AUTOSAR XML (schema 00048)
package /MICROSAR/ComM_swc
  mode declaration group ComMMode: initial-mode=COMM_NO_COMMUNICATION
    mode COMM_NO_COMMUNICATION
    mode COMM_SILENT_COMMUNICATION
    mode COMM_FULL_COMMUNICATION
  data type mapping set ComMMode_DataTypeMappingSet: mode-request-type-map{implementation-data-type=ComM_ModeType, mode-group=ComMMode}  # Data Mapping for the Mode Declaration Group ComMMode.
package /MICROSAR/ComM_swc/DataTypes
  4 x impl type, all with category=TYPE_REFERENCE:
    ComM_ModeType: compu {0=COMM_NO_COMMUNICATION, 1=COMM_SILENT_COMMUNICATION, 2=COMM_FULL_COMMUNICATION}, range raw 0..3, implementation-data-type=uint8
    ComM_InhibitionStatusType: range raw 0..255, implementation-data-type=uint8
    ComM_UserHandleType: range raw 0..65535, implementation-data-type=uint16
    NetworkHandleType: range raw 0..255, implementation-data-type=uint8, type-emitter=ComM
package /MICROSAR/ComM_swc/Interfaces
  4 x client server interface, all with is-service=true, service-kind=COM-MANAGER:
    ComM_UserRequest
      5 x operation:
        RequestComMode: possible-error=[ComM_UserRequest/E_NOT_OK, E_MODE_LIMITATION]
          arg ComMode: type=ComM_ModeType, direction=IN
        GetCurrentComMode: possible-error=ComM_UserRequest/E_NOT_OK
          arg ComMode: type=ComM_ModeType, direction=OUT
        GetMaxComMode: possible-error=ComM_UserRequest/E_NOT_OK
          arg ComMode: type=ComM_ModeType, direction=OUT
        GetRequestedComMode: possible-error=ComM_UserRequest/E_NOT_OK
          arg ComMode: type=ComM_ModeType, direction=OUT
        GetCurrentPNCComMode: possible-error=[ComM_UserRequest/E_NOT_OK, E_MULTIPLE_PNC_ASSIGNED, COMM_E_NO_PNC_ASSIGNED]
          arg ComMode: type=ComM_ModeType, direction=OUT
      4 x error:
        E_NOT_OK: error-code=1
        E_MODE_LIMITATION: error-code=2
        E_MULTIPLE_PNC_ASSIGNED: error-code=4
        COMM_E_NO_PNC_ASSIGNED: error-code=5
    ComM_ECUModeLimitation
      4 x operation, all with possible-error=ComM_ECUModeLimitation/E_NOT_OK:
        LimitECUToNoComMode
          arg Status: type=boolean, direction=IN
        ReadInhibitCounter
          arg CounterValue: type=uint16, direction=OUT
        ResetInhibitCounter
        SetECUGroupClassification
          arg Status: type=ComM_InhibitionStatusType, direction=IN
      error E_NOT_OK: error-code=1
    ComM_ChannelWakeUp
      operation PreventWakeUp: possible-error=ComM_ChannelWakeUp/E_NOT_OK
        arg Status: type=boolean, direction=IN
      operation GetInhibitionStatus: possible-error=ComM_ChannelWakeUp/E_NOT_OK
        arg Status: type=ComM_InhibitionStatusType, direction=OUT
      error E_NOT_OK: error-code=1
    ComM_ChannelLimitation
      operation LimitChannelToNoComMode: possible-error=ComM_ChannelLimitation/E_NOT_OK
        arg Status: type=boolean, direction=IN
      operation GetInhibitionStatus: possible-error=ComM_ChannelLimitation/E_NOT_OK
        arg Status: type=ComM_InhibitionStatusType, direction=OUT
      error E_NOT_OK: error-code=1
  mode switch interface ComM_CurrentMode: is-service=true, service-kind=COM-MANAGER
    mode group currentMode: type=ComMMode
package /MICROSAR/ComM_swc/ComponentTypes
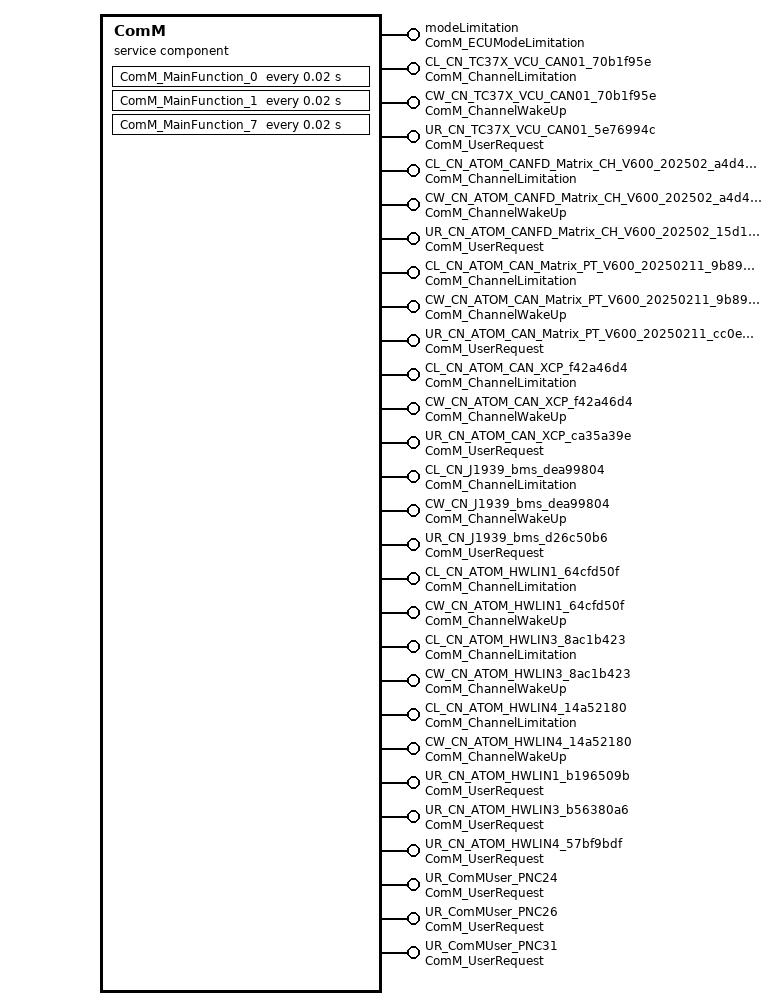
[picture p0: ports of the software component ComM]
  service sw component type ComM: category=SERVICE_COMPONENT
    28 x provide port:
      modeLimitation: provided-interface=ComM_ECUModeLimitation
      CL_CN_TC37X_VCU_CAN01_70b1f95e: provided-interface=ComM_ChannelLimitation
      CW_CN_TC37X_VCU_CAN01_70b1f95e: provided-interface=ComM_ChannelWakeUp
      UR_CN_TC37X_VCU_CAN01_5e76994c: provided-interface=ComM_UserRequest
      CL_CN_ATOM_CANFD_Matrix_CH_V600_202502_a4d436ac: provided-interface=ComM_ChannelLimitation
      CW_CN_ATOM_CANFD_Matrix_CH_V600_202502_a4d436ac: provided-interface=ComM_ChannelWakeUp
      UR_CN_ATOM_CANFD_Matrix_CH_V600_202502_15d11ab0: provided-interface=ComM_UserRequest
      CL_CN_ATOM_CAN_Matrix_PT_V600_20250211_9b894f3d: provided-interface=ComM_ChannelLimitation
      CW_CN_ATOM_CAN_Matrix_PT_V600_20250211_9b894f3d: provided-interface=ComM_ChannelWakeUp
      UR_CN_ATOM_CAN_Matrix_PT_V600_20250211_cc0efb79: provided-interface=ComM_UserRequest
      CL_CN_ATOM_CAN_XCP_f42a46d4: provided-interface=ComM_ChannelLimitation
      CW_CN_ATOM_CAN_XCP_f42a46d4: provided-interface=ComM_ChannelWakeUp
      UR_CN_ATOM_CAN_XCP_ca35a39e: provided-interface=ComM_UserRequest
      CL_CN_J1939_bms_dea99804: provided-interface=ComM_ChannelLimitation
      CW_CN_J1939_bms_dea99804: provided-interface=ComM_ChannelWakeUp
      UR_CN_J1939_bms_d26c50b6: provided-interface=ComM_UserRequest
      CL_CN_ATOM_HWLIN1_64cfd50f: provided-interface=ComM_ChannelLimitation
      CW_CN_ATOM_HWLIN1_64cfd50f: provided-interface=ComM_ChannelWakeUp
      CL_CN_ATOM_HWLIN3_8ac1b423: provided-interface=ComM_ChannelLimitation
      CW_CN_ATOM_HWLIN3_8ac1b423: provided-interface=ComM_ChannelWakeUp
      CL_CN_ATOM_HWLIN4_14a52180: provided-interface=ComM_ChannelLimitation
      CW_CN_ATOM_HWLIN4_14a52180: provided-interface=ComM_ChannelWakeUp
      UR_CN_ATOM_HWLIN1_b196509b: provided-interface=ComM_UserRequest
      UR_CN_ATOM_HWLIN3_b56380a6: provided-interface=ComM_UserRequest
      UR_CN_ATOM_HWLIN4_57bf9bdf: provided-interface=ComM_UserRequest
      UR_ComMUser_PNC24: provided-interface=ComM_UserRequest
      UR_ComMUser_PNC26: provided-interface=ComM_UserRequest
      UR_ComMUser_PNC31: provided-interface=ComM_UserRequest
    behavior ComMInternalBehavior: data-type-mapping=ComMMode_DataTypeMappingSet, handle-termination-and-restart=NO-SUPPORT, included-data-type-set=data-type=[ComM_ModeType, ComM_InhibitionStatusType, ComM_UserHandleType, NetworkHandleType]
      timing event Timer_ComM_MainFunction_0: start-on-event=ComM_MainFunction_0, period=0.02
      4 x operation invoked event:
        OpEventLimitECUToNoComMode_LimitECUToNoComMode_modeLimitation: start-on-event=LimitECUToNoComMode, operation=modeLimitation.LimitECUToNoComMode
        OpEventReadInhibitCounter_ReadInhibitCounter_modeLimitation: start-on-event=ReadInhibitCounter, operation=modeLimitation.ReadInhibitCounter
        OpEventResetInhibitCounter_ResetInhibitCounter_modeLimitation: start-on-event=ResetInhibitCounter, operation=modeLimitation.ResetInhibitCounter
        OpEventSetECUGroupClassification_SetECUGroupClassification_modeLimitation: start-on-event=SetECUGroupClassification, operation=modeLimitation.SetECUGroupClassification
      timing event Timer_ComM_MainFunction_1: start-on-event=ComM_MainFunction_1, period=0.02
      8 x operation invoked event:
        OpEventGetInhibitionStatus_GetInhibitionStatus_CL_CN_TC37X_VCU_CAN01_70b1f95e: start-on-event=GetInhibitionStatus, operation=CL_CN_TC37X_VCU_CAN01_70b1f95e.GetInhibitionStatus
        OpEventGetInhibitionStatus_GetInhibitionStatus_CW_CN_TC37X_VCU_CAN01_70b1f95e: start-on-event=GetInhibitionStatus, operation=CW_CN_TC37X_VCU_CAN01_70b1f95e.GetInhibitionStatus
        OpEventLimitChannelToNoComMode_LimitChannelToNoComMode_CL_CN_TC37X_VCU_CAN01_70b1f95e: start-on-event=LimitChannelToNoComMode, operation=CL_CN_TC37X_VCU_CAN01_70b1f95e.LimitChannelToNoComMode
        OpEventPreventWakeUp_PreventWakeUp_CW_CN_TC37X_VCU_CAN01_70b1f95e: start-on-event=PreventWakeUp, operation=CW_CN_TC37X_VCU_CAN01_70b1f95e.PreventWakeUp
        OpEventRequestComMode_RequestComMode_UR_CN_TC37X_VCU_CAN01_5e76994c: start-on-event=RequestComMode, operation=UR_CN_TC37X_VCU_CAN01_5e76994c.RequestComMode
        OpEventGetCurrentComMode_GetCurrentComMode_UR_CN_TC37X_VCU_CAN01_5e76994c: start-on-event=GetCurrentComMode, operation=UR_CN_TC37X_VCU_CAN01_5e76994c.GetCurrentComMode
        OpEventGetMaxComMode_GetMaxComMode_UR_CN_TC37X_VCU_CAN01_5e76994c: start-on-event=GetMaxComMode, operation=UR_CN_TC37X_VCU_CAN01_5e76994c.GetMaxComMode
        OpEventGetRequestedComMode_GetRequestedComMode_UR_CN_TC37X_VCU_CAN01_5e76994c: start-on-event=GetRequestedComMode, operation=UR_CN_TC37X_VCU_CAN01_5e76994c.GetRequestedComMode
      5 x timing event, all with period=0.02:
        Timer_ComM_MainFunction_{2..6}: start-on-event=ComM_MainFunction_{2..6}
      8 x operation invoked event:
        OpEventGetInhibitionStatus_GetInhibitionStatus_CL_CN_ATOM_CANFD_Matrix_CH_V600_202502_a4d436ac: start-on-event=GetInhibitionStatus, operation=CL_CN_ATOM_CANFD_Matrix_CH_V600_202502_a4d436ac.GetInhibitionStatus
        OpEventGetInhibitionStatus_GetInhibitionStatus_CW_CN_ATOM_CANFD_Matrix_CH_V600_202502_a4d436ac: start-on-event=GetInhibitionStatus, operation=CW_CN_ATOM_CANFD_Matrix_CH_V600_202502_a4d436ac.GetInhibitionStatus
        OpEventLimitChannelToNoComMode_LimitChannelToNoComMode_CL_CN_ATOM_CANFD_Matrix_CH_V600_202502_a4d436ac: start-on-event=LimitChannelToNoComMode, operation=CL_CN_ATOM_CANFD_Matrix_CH_V600_202502_a4d436ac.LimitChannelToNoComMode
        OpEventPreventWakeUp_PreventWakeUp_CW_CN_ATOM_CANFD_Matrix_CH_V600_202502_a4d436ac: start-on-event=PreventWakeUp, operation=CW_CN_ATOM_CANFD_Matrix_CH_V600_202502_a4d436ac.PreventWakeUp
        OpEventRequestComMode_RequestComMode_UR_CN_ATOM_CANFD_Matrix_CH_V600_202502_15d11ab0: start-on-event=RequestComMode, operation=UR_CN_ATOM_CANFD_Matrix_CH_V600_202502_15d11ab0.RequestComMode
        OpEventGetCurrentComMode_GetCurrentComMode_UR_CN_ATOM_CANFD_Matrix_CH_V600_202502_15d11ab0: start-on-event=GetCurrentComMode, operation=UR_CN_ATOM_CANFD_Matrix_CH_V600_202502_15d11ab0.GetCurrentComMode
        OpEventGetMaxComMode_GetMaxComMode_UR_CN_ATOM_CANFD_Matrix_CH_V600_202502_15d11ab0: start-on-event=GetMaxComMode, operation=UR_CN_ATOM_CANFD_Matrix_CH_V600_202502_15d11ab0.GetMaxComMode
        OpEventGetRequestedComMode_GetRequestedComMode_UR_CN_ATOM_CANFD_Matrix_CH_V600_202502_15d11ab0: start-on-event=GetRequestedComMode, operation=UR_CN_ATOM_CANFD_Matrix_CH_V600_202502_15d11ab0.GetRequestedComMode
      timing event Timer_ComM_MainFunction_7: start-on-event=ComM_MainFunction_7, period=0.02
      71 x operation invoked event:
        OpEventGetInhibitionStatus_GetInhibitionStatus_CL_CN_ATOM_CAN_Matrix_PT_V600_20250211_9b894f3d: start-on-event=GetInhibitionStatus, operation=CL_CN_ATOM_CAN_Matrix_PT_V600_20250211_9b894f3d.GetInhibitionStatus
        OpEventGetInhibitionStatus_GetInhibitionStatus_CW_CN_ATOM_CAN_Matrix_PT_V600_20250211_9b894f3d: start-on-event=GetInhibitionStatus, operation=CW_CN_ATOM_CAN_Matrix_PT_V600_20250211_9b894f3d.GetInhibitionStatus
        OpEventLimitChannelToNoComMode_LimitChannelToNoComMode_CL_CN_ATOM_CAN_Matrix_PT_V600_20250211_9b894f3d: start-on-event=LimitChannelToNoComMode, operation=CL_CN_ATOM_CAN_Matrix_PT_V600_20250211_9b894f3d.LimitChannelToNoComMode
        OpEventPreventWakeUp_PreventWakeUp_CW_CN_ATOM_CAN_Matrix_PT_V600_20250211_9b894f3d: start-on-event=PreventWakeUp, operation=CW_CN_ATOM_CAN_Matrix_PT_V600_20250211_9b894f3d.PreventWakeUp
        OpEventRequestComMode_RequestComMode_UR_CN_ATOM_CAN_Matrix_PT_V600_20250211_cc0efb79: start-on-event=RequestComMode, operation=UR_CN_ATOM_CAN_Matrix_PT_V600_20250211_cc0efb79.RequestComMode
        OpEventGetCurrentComMode_GetCurrentComMode_UR_CN_ATOM_CAN_Matrix_PT_V600_20250211_cc0efb79: start-on-event=GetCurrentComMode, operation=UR_CN_ATOM_CAN_Matrix_PT_V600_20250211_cc0efb79.GetCurrentComMode
        OpEventGetMaxComMode_GetMaxComMode_UR_CN_ATOM_CAN_Matrix_PT_V600_20250211_cc0efb79: start-on-event=GetMaxComMode, operation=UR_CN_ATOM_CAN_Matrix_PT_V600_20250211_cc0efb79.GetMaxComMode
        OpEventGetRequestedComMode_GetRequestedComMode_UR_CN_ATOM_CAN_Matrix_PT_V600_20250211_cc0efb79: start-on-event=GetRequestedComMode, operation=UR_CN_ATOM_CAN_Matrix_PT_V600_20250211_cc0efb79.GetRequestedComMode
        OpEventGetInhibitionStatus_GetInhibitionStatus_CL_CN_ATOM_CAN_XCP_f42a46d4: start-on-event=GetInhibitionStatus, operation=CL_CN_ATOM_CAN_XCP_f42a46d4.GetInhibitionStatus
        OpEventGetInhibitionStatus_GetInhibitionStatus_CW_CN_ATOM_CAN_XCP_f42a46d4: start-on-event=GetInhibitionStatus, operation=CW_CN_ATOM_CAN_XCP_f42a46d4.GetInhibitionStatus
        OpEventLimitChannelToNoComMode_LimitChannelToNoComMode_CL_CN_ATOM_CAN_XCP_f42a46d4: start-on-event=LimitChannelToNoComMode, operation=CL_CN_ATOM_CAN_XCP_f42a46d4.LimitChannelToNoComMode
        OpEventPreventWakeUp_PreventWakeUp_CW_CN_ATOM_CAN_XCP_f42a46d4: start-on-event=PreventWakeUp, operation=CW_CN_ATOM_CAN_XCP_f42a46d4.PreventWakeUp
        OpEventRequestComMode_RequestComMode_UR_CN_ATOM_CAN_XCP_ca35a39e: start-on-event=RequestComMode, operation=UR_CN_ATOM_CAN_XCP_ca35a39e.RequestComMode
        OpEventGetCurrentComMode_GetCurrentComMode_UR_CN_ATOM_CAN_XCP_ca35a39e: start-on-event=GetCurrentComMode, operation=UR_CN_ATOM_CAN_XCP_ca35a39e.GetCurrentComMode
        OpEventGetMaxComMode_GetMaxComMode_UR_CN_ATOM_CAN_XCP_ca35a39e: start-on-event=GetMaxComMode, operation=UR_CN_ATOM_CAN_XCP_ca35a39e.GetMaxComMode
        OpEventGetRequestedComMode_GetRequestedComMode_UR_CN_ATOM_CAN_XCP_ca35a39e: start-on-event=GetRequestedComMode, operation=UR_CN_ATOM_CAN_XCP_ca35a39e.GetRequestedComMode
        OpEventGetInhibitionStatus_GetInhibitionStatus_CL_CN_J1939_bms_dea99804: start-on-event=GetInhibitionStatus, operation=CL_CN_J1939_bms_dea99804.GetInhibitionStatus
        OpEventGetInhibitionStatus_GetInhibitionStatus_CW_CN_J1939_bms_dea99804: start-on-event=GetInhibitionStatus, operation=CW_CN_J1939_bms_dea99804.GetInhibitionStatus
        OpEventLimitChannelToNoComMode_LimitChannelToNoComMode_CL_CN_J1939_bms_dea99804: start-on-event=LimitChannelToNoComMode, operation=CL_CN_J1939_bms_dea99804.LimitChannelToNoComMode
        OpEventPreventWakeUp_PreventWakeUp_CW_CN_J1939_bms_dea99804: start-on-event=PreventWakeUp, operation=CW_CN_J1939_bms_dea99804.PreventWakeUp
        OpEventRequestComMode_RequestComMode_UR_CN_J1939_bms_d26c50b6: start-on-event=RequestComMode, operation=UR_CN_J1939_bms_d26c50b6.RequestComMode
        OpEventGetCurrentComMode_GetCurrentComMode_UR_CN_J1939_bms_d26c50b6: start-on-event=GetCurrentComMode, operation=UR_CN_J1939_bms_d26c50b6.GetCurrentComMode
        OpEventGetMaxComMode_GetMaxComMode_UR_CN_J1939_bms_d26c50b6: start-on-event=GetMaxComMode, operation=UR_CN_J1939_bms_d26c50b6.GetMaxComMode
        OpEventGetRequestedComMode_GetRequestedComMode_UR_CN_J1939_bms_d26c50b6: start-on-event=GetRequestedComMode, operation=UR_CN_J1939_bms_d26c50b6.GetRequestedComMode
        OpEventGetInhibitionStatus_GetInhibitionStatus_CL_CN_ATOM_HWLIN1_64cfd50f: start-on-event=GetInhibitionStatus, operation=CL_CN_ATOM_HWLIN1_64cfd50f.GetInhibitionStatus
        OpEventGetInhibitionStatus_GetInhibitionStatus_CW_CN_ATOM_HWLIN1_64cfd50f: start-on-event=GetInhibitionStatus, operation=CW_CN_ATOM_HWLIN1_64cfd50f.GetInhibitionStatus
        OpEventGetInhibitionStatus_GetInhibitionStatus_CL_CN_ATOM_HWLIN3_8ac1b423: start-on-event=GetInhibitionStatus, operation=CL_CN_ATOM_HWLIN3_8ac1b423.GetInhibitionStatus
        OpEventGetInhibitionStatus_GetInhibitionStatus_CW_CN_ATOM_HWLIN3_8ac1b423: start-on-event=GetInhibitionStatus, operation=CW_CN_ATOM_HWLIN3_8ac1b423.GetInhibitionStatus
        OpEventGetInhibitionStatus_GetInhibitionStatus_CL_CN_ATOM_HWLIN4_14a52180: start-on-event=GetInhibitionStatus, operation=CL_CN_ATOM_HWLIN4_14a52180.GetInhibitionStatus
        OpEventGetInhibitionStatus_GetInhibitionStatus_CW_CN_ATOM_HWLIN4_14a52180: start-on-event=GetInhibitionStatus, operation=CW_CN_ATOM_HWLIN4_14a52180.GetInhibitionStatus
        OpEventLimitChannelToNoComMode_LimitChannelToNoComMode_CL_CN_ATOM_HWLIN1_64cfd50f: start-on-event=LimitChannelToNoComMode, operation=CL_CN_ATOM_HWLIN1_64cfd50f.LimitChannelToNoComMode
        OpEventLimitChannelToNoComMode_LimitChannelToNoComMode_CL_CN_ATOM_HWLIN3_8ac1b423: start-on-event=LimitChannelToNoComMode, operation=CL_CN_ATOM_HWLIN3_8ac1b423.LimitChannelToNoComMode
        OpEventLimitChannelToNoComMode_LimitChannelToNoComMode_CL_CN_ATOM_HWLIN4_14a52180: start-on-event=LimitChannelToNoComMode, operation=CL_CN_ATOM_HWLIN4_14a52180.LimitChannelToNoComMode
        OpEventPreventWakeUp_PreventWakeUp_CW_CN_ATOM_HWLIN1_64cfd50f: start-on-event=PreventWakeUp, operation=CW_CN_ATOM_HWLIN1_64cfd50f.PreventWakeUp
        OpEventPreventWakeUp_PreventWakeUp_CW_CN_ATOM_HWLIN3_8ac1b423: start-on-event=PreventWakeUp, operation=CW_CN_ATOM_HWLIN3_8ac1b423.PreventWakeUp
        OpEventPreventWakeUp_PreventWakeUp_CW_CN_ATOM_HWLIN4_14a52180: start-on-event=PreventWakeUp, operation=CW_CN_ATOM_HWLIN4_14a52180.PreventWakeUp
        OpEventRequestComMode_RequestComMode_UR_CN_ATOM_HWLIN1_b196509b: start-on-event=RequestComMode, operation=UR_CN_ATOM_HWLIN1_b196509b.RequestComMode
        OpEventRequestComMode_RequestComMode_UR_CN_ATOM_HWLIN3_b56380a6: start-on-event=RequestComMode, operation=UR_CN_ATOM_HWLIN3_b56380a6.RequestComMode
        OpEventRequestComMode_RequestComMode_UR_CN_ATOM_HWLIN4_57bf9bdf: start-on-event=RequestComMode, operation=UR_CN_ATOM_HWLIN4_57bf9bdf.RequestComMode
        OpEventGetCurrentComMode_GetCurrentComMode_UR_CN_ATOM_HWLIN1_b196509b: start-on-event=GetCurrentComMode, operation=UR_CN_ATOM_HWLIN1_b196509b.GetCurrentComMode
        OpEventGetCurrentComMode_GetCurrentComMode_UR_CN_ATOM_HWLIN3_b56380a6: start-on-event=GetCurrentComMode, operation=UR_CN_ATOM_HWLIN3_b56380a6.GetCurrentComMode
        OpEventGetCurrentComMode_GetCurrentComMode_UR_CN_ATOM_HWLIN4_57bf9bdf: start-on-event=GetCurrentComMode, operation=UR_CN_ATOM_HWLIN4_57bf9bdf.GetCurrentComMode
        OpEventGetMaxComMode_GetMaxComMode_UR_CN_ATOM_HWLIN1_b196509b: start-on-event=GetMaxComMode, operation=UR_CN_ATOM_HWLIN1_b196509b.GetMaxComMode
        OpEventGetMaxComMode_GetMaxComMode_UR_CN_ATOM_HWLIN3_b56380a6: start-on-event=GetMaxComMode, operation=UR_CN_ATOM_HWLIN3_b56380a6.GetMaxComMode
        OpEventGetMaxComMode_GetMaxComMode_UR_CN_ATOM_HWLIN4_57bf9bdf: start-on-event=GetMaxComMode, operation=UR_CN_ATOM_HWLIN4_57bf9bdf.GetMaxComMode
        OpEventGetRequestedComMode_GetRequestedComMode_UR_CN_ATOM_HWLIN1_b196509b: start-on-event=GetRequestedComMode, operation=UR_CN_ATOM_HWLIN1_b196509b.GetRequestedComMode
        OpEventGetRequestedComMode_GetRequestedComMode_UR_CN_ATOM_HWLIN3_b56380a6: start-on-event=GetRequestedComMode, operation=UR_CN_ATOM_HWLIN3_b56380a6.GetRequestedComMode
        OpEventGetRequestedComMode_GetRequestedComMode_UR_CN_ATOM_HWLIN4_57bf9bdf: start-on-event=GetRequestedComMode, operation=UR_CN_ATOM_HWLIN4_57bf9bdf.GetRequestedComMode
        OpEventRequestComMode_RequestComMode_UR_ComMUser_PNC24: start-on-event=RequestComMode, operation=UR_ComMUser_PNC24.RequestComMode
        OpEventRequestComMode_RequestComMode_UR_ComMUser_PNC26: start-on-event=RequestComMode, operation=UR_ComMUser_PNC26.RequestComMode
        OpEventGetCurrentComMode_GetCurrentComMode_UR_ComMUser_PNC24: start-on-event=GetCurrentComMode, operation=UR_ComMUser_PNC24.GetCurrentComMode
        OpEventGetCurrentComMode_GetCurrentComMode_UR_ComMUser_PNC26: start-on-event=GetCurrentComMode, operation=UR_ComMUser_PNC26.GetCurrentComMode
        OpEventGetCurrentPNCComMode_GetCurrentPNCComMode_UR_CN_ATOM_CANFD_Matrix_CH_V600_202502_15d11ab0: start-on-event=GetCurrentPNCComMode, operation=UR_CN_ATOM_CANFD_Matrix_CH_V600_202502_15d11ab0.GetCurrentPNCComMode
        OpEventGetCurrentPNCComMode_GetCurrentPNCComMode_UR_CN_ATOM_CAN_Matrix_PT_V600_20250211_cc0efb79: start-on-event=GetCurrentPNCComMode, operation=UR_CN_ATOM_CAN_Matrix_PT_V600_20250211_cc0efb79.GetCurrentPNCComMode
        OpEventGetCurrentPNCComMode_GetCurrentPNCComMode_UR_CN_ATOM_CAN_XCP_ca35a39e: start-on-event=GetCurrentPNCComMode, operation=UR_CN_ATOM_CAN_XCP_ca35a39e.GetCurrentPNCComMode
        OpEventGetCurrentPNCComMode_GetCurrentPNCComMode_UR_CN_ATOM_HWLIN1_b196509b: start-on-event=GetCurrentPNCComMode, operation=UR_CN_ATOM_HWLIN1_b196509b.GetCurrentPNCComMode
        OpEventGetCurrentPNCComMode_GetCurrentPNCComMode_UR_CN_ATOM_HWLIN3_b56380a6: start-on-event=GetCurrentPNCComMode, operation=UR_CN_ATOM_HWLIN3_b56380a6.GetCurrentPNCComMode
        OpEventGetCurrentPNCComMode_GetCurrentPNCComMode_UR_CN_ATOM_HWLIN4_57bf9bdf: start-on-event=GetCurrentPNCComMode, operation=UR_CN_ATOM_HWLIN4_57bf9bdf.GetCurrentPNCComMode
        OpEventGetCurrentPNCComMode_GetCurrentPNCComMode_UR_CN_J1939_bms_d26c50b6: start-on-event=GetCurrentPNCComMode, operation=UR_CN_J1939_bms_d26c50b6.GetCurrentPNCComMode
        OpEventGetCurrentPNCComMode_GetCurrentPNCComMode_UR_CN_TC37X_VCU_CAN01_5e76994c: start-on-event=GetCurrentPNCComMode, operation=UR_CN_TC37X_VCU_CAN01_5e76994c.GetCurrentPNCComMode
        OpEventGetCurrentPNCComMode_GetCurrentPNCComMode_UR_ComMUser_PNC24: start-on-event=GetCurrentPNCComMode, operation=UR_ComMUser_PNC24.GetCurrentPNCComMode
        OpEventGetCurrentPNCComMode_GetCurrentPNCComMode_UR_ComMUser_PNC26: start-on-event=GetCurrentPNCComMode, operation=UR_ComMUser_PNC26.GetCurrentPNCComMode
        OpEventGetMaxComMode_GetMaxComMode_UR_ComMUser_PNC24: start-on-event=GetMaxComMode, operation=UR_ComMUser_PNC24.GetMaxComMode
        OpEventGetMaxComMode_GetMaxComMode_UR_ComMUser_PNC26: start-on-event=GetMaxComMode, operation=UR_ComMUser_PNC26.GetMaxComMode
        OpEventGetRequestedComMode_GetRequestedComMode_UR_ComMUser_PNC24: start-on-event=GetRequestedComMode, operation=UR_ComMUser_PNC24.GetRequestedComMode
        OpEventGetRequestedComMode_GetRequestedComMode_UR_ComMUser_PNC26: start-on-event=GetRequestedComMode, operation=UR_ComMUser_PNC26.GetRequestedComMode
        OpEventRequestComMode_RequestComMode_UR_ComMUser_PNC31: start-on-event=RequestComMode, operation=UR_ComMUser_PNC31.RequestComMode
        OpEventGetCurrentComMode_GetCurrentComMode_UR_ComMUser_PNC31: start-on-event=GetCurrentComMode, operation=UR_ComMUser_PNC31.GetCurrentComMode
        OpEventGetCurrentPNCComMode_GetCurrentPNCComMode_UR_ComMUser_PNC31: start-on-event=GetCurrentPNCComMode, operation=UR_ComMUser_PNC31.GetCurrentPNCComMode
        OpEventGetMaxComMode_GetMaxComMode_UR_ComMUser_PNC31: start-on-event=GetMaxComMode, operation=UR_ComMUser_PNC31.GetMaxComMode
        OpEventGetRequestedComMode_GetRequestedComMode_UR_ComMUser_PNC31: start-on-event=GetRequestedComMode, operation=UR_ComMUser_PNC31.GetRequestedComMode
      port-api-options:
        enable-take-address=true, indirect-api=false, port=modeLimitation
        {enable-take-address=true, indirect-api=false, port-defined-argument-value{value=0, value-type=NetworkHandleType}, port=CL_CN_ATOM_CANFD_Matrix_CH_V600_202502_a4d436ac}
        {enable-take-address=true, indirect-api=false, port-defined-argument-value{value=0, value-type=NetworkHandleType}, port=CW_CN_ATOM_CANFD_Matrix_CH_V600_202502_a4d436ac}
        {enable-take-address=true, indirect-api=false, port-defined-argument-value{value=0, value-type=ComM_UserHandleType}, port=UR_CN_ATOM_CANFD_Matrix_CH_V600_202502_15d11ab0}
        {enable-take-address=true, indirect-api=false, port-defined-argument-value{value=1, value-type=NetworkHandleType}, port=CL_CN_ATOM_CAN_Matrix_PT_V600_20250211_9b894f3d}
        {enable-take-address=true, indirect-api=false, port-defined-argument-value{value=1, value-type=NetworkHandleType}, port=CW_CN_ATOM_CAN_Matrix_PT_V600_20250211_9b894f3d}
        {enable-take-address=true, indirect-api=false, port-defined-argument-value{value=1, value-type=ComM_UserHandleType}, port=UR_CN_ATOM_CAN_Matrix_PT_V600_20250211_cc0efb79}
        {enable-take-address=true, indirect-api=false, port-defined-argument-value{value=2, value-type=NetworkHandleType}, port=CL_CN_ATOM_CAN_XCP_f42a46d4}
        {enable-take-address=true, indirect-api=false, port-defined-argument-value{value=2, value-type=NetworkHandleType}, port=CW_CN_ATOM_CAN_XCP_f42a46d4}
        {enable-take-address=true, indirect-api=false, port-defined-argument-value{value=3, value-type=NetworkHandleType}, port=CL_CN_TC37X_VCU_CAN01_70b1f95e}
        {enable-take-address=true, indirect-api=false, port-defined-argument-value{value=3, value-type=NetworkHandleType}, port=CW_CN_TC37X_VCU_CAN01_70b1f95e}
        {enable-take-address=true, indirect-api=false, port-defined-argument-value{value=2, value-type=ComM_UserHandleType}, port=UR_CN_ATOM_CAN_XCP_ca35a39e}
        {enable-take-address=true, indirect-api=false, port-defined-argument-value{value=3, value-type=ComM_UserHandleType}, port=UR_CN_TC37X_VCU_CAN01_5e76994c}
        {enable-take-address=true, indirect-api=false, port-defined-argument-value{value=4, value-type=NetworkHandleType}, port=CL_CN_J1939_bms_dea99804}
        {enable-take-address=true, indirect-api=false, port-defined-argument-value{value=4, value-type=NetworkHandleType}, port=CW_CN_J1939_bms_dea99804}
        {enable-take-address=true, indirect-api=false, port-defined-argument-value{value=4, value-type=ComM_UserHandleType}, port=UR_CN_J1939_bms_d26c50b6}
        {enable-take-address=true, indirect-api=false, port-defined-argument-value{value=5, value-type=NetworkHandleType}, port=CL_CN_ATOM_HWLIN1_64cfd50f}
        {enable-take-address=true, indirect-api=false, port-defined-argument-value{value=5, value-type=NetworkHandleType}, port=CW_CN_ATOM_HWLIN1_64cfd50f}
        {enable-take-address=true, indirect-api=false, port-defined-argument-value{value=6, value-type=NetworkHandleType}, port=CL_CN_ATOM_HWLIN3_8ac1b423}
        {enable-take-address=true, indirect-api=false, port-defined-argument-value{value=6, value-type=NetworkHandleType}, port=CW_CN_ATOM_HWLIN3_8ac1b423}
        {enable-take-address=true, indirect-api=false, port-defined-argument-value{value=7, value-type=NetworkHandleType}, port=CL_CN_ATOM_HWLIN4_14a52180}
        {enable-take-address=true, indirect-api=false, port-defined-argument-value{value=7, value-type=NetworkHandleType}, port=CW_CN_ATOM_HWLIN4_14a52180}
        {enable-take-address=true, indirect-api=false, port-defined-argument-value{value=5, value-type=ComM_UserHandleType}, port=UR_CN_ATOM_HWLIN1_b196509b}
        {enable-take-address=true, indirect-api=false, port-defined-argument-value{value=6, value-type=ComM_UserHandleType}, port=UR_CN_ATOM_HWLIN3_b56380a6}
        {enable-take-address=true, indirect-api=false, port-defined-argument-value{value=7, value-type=ComM_UserHandleType}, port=UR_CN_ATOM_HWLIN4_57bf9bdf}
        {enable-take-address=true, indirect-api=false, port-defined-argument-value{value=8, value-type=ComM_UserHandleType}, port=UR_ComMUser_PNC24}
        {enable-take-address=true, indirect-api=false, port-defined-argument-value{value=9, value-type=ComM_UserHandleType}, port=UR_ComMUser_PNC26}
        {enable-take-address=true, indirect-api=false, port-defined-argument-value{value=10, value-type=ComM_UserHandleType}, port=UR_ComMUser_PNC31}
      20 x runnable, all with can-be-invoked-concurrently=true:
        ComM_MainFunction_0
        GetInhibitionStatus: symbol=ComM_GetInhibitionStatus
        LimitECUToNoComMode: symbol=ComM_LimitECUToNoComMode
        ReadInhibitCounter: symbol=ComM_ReadInhibitCounter
        ResetInhibitCounter: symbol=ComM_ResetInhibitCounter
        SetECUGroupClassification: symbol=ComM_SetECUGroupClassification
        LimitChannelToNoComMode: symbol=ComM_LimitChannelToNoComMode
        PreventWakeUp: symbol=ComM_PreventWakeUp
        RequestComMode: symbol=ComM_RequestComMode
        GetCurrentComMode: symbol=ComM_GetCurrentComMode
        GetMaxComMode: symbol=ComM_GetMaxComMode
        GetRequestedComMode: symbol=ComM_GetRequestedComMode
        ComM_MainFunction_{1..7}
        GetCurrentPNCComMode: symbol=ComM_GetCurrentPNCComMode
  swc implementation ComMImplementation: programming-language=C, behavior=ComMInternalBehavior
